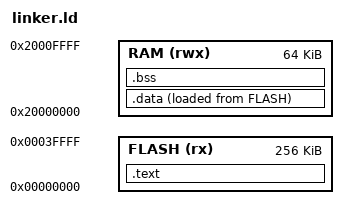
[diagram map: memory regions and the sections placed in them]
ENTRY(Reset_Handler)

MEMORY
{
    FLASH (rx) : ORIGIN = 0x00000000, LENGTH = 256K
    RAM (rwx)  : ORIGIN = 0x20000000, LENGTH = 64K
}

_estack = ORIGIN(RAM) + LENGTH(RAM);

SECTIONS
{
    .text :
    {
        KEEP(*(.isr_vector))
        *(.text)
        *(.text.*)
        *(.rodata)
        *(.rodata.*)
        . = ALIGN(4);
        _etext = .;
    } > FLASH

    _sidata = LOADADDR(.data);

    .data :
    {
        . = ALIGN(4);
        _sdata = .;
        *(.data)
        *(.data.*)
        . = ALIGN(4);
        _edata = .;
    } > RAM AT > FLASH

    .bss :
    {
        . = ALIGN(4);
        _sbss = .;
        __bss_start__ = .;
        *(.bss)
        *(.bss.*)
        *(COMMON)
        . = ALIGN(4);
        _ebss = .;
        __bss_end__ = .;
    } > RAM

    . = ALIGN(4);
    end = .;
    _end = .;
}
